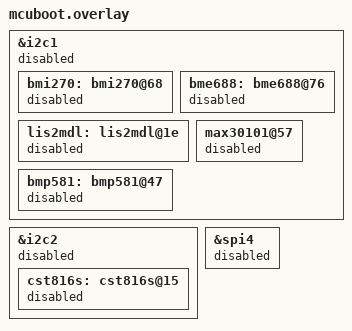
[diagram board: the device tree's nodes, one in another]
/* Disable most of the peripherals
    and drivers as mcuboot 
    does not require them.
*/
&i2c1 {
    status = "disabled";    
    bmi270: bmi270@68 {
        status = "disabled";    
    };
    bme688: bme688@76 {
       status = "disabled";    
    };
    lis2mdl: lis2mdl@1e {
        status = "disabled";   
    };

    max30101@57 {
        status = "disabled";   
    };
    bmp581: bmp581@47 {
        status = "disabled";
    };
};

&i2c2 {
    status = "disabled";
    cst816s: cst816s@15 {
		status = "disabled";
	};
};

&spi4{
    status = "disabled";
};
